# MSPM0G110X register map
Vendor: Texas Instruments; File version: This preliminary header file does not have a version number - build date: 2023-02-21 16:25:48
CPU: CM0 r0p1, little endian, MPU, no FPU, 3 interrupt priority bits
Registers are 32-bit, read-write, reset 0x0 unless marked. A register's access mark holds for its fields unless they carry their own. Offsets are from the block's base; [hi:lo] are bit positions.

## WWDT1 — WWDT
Base 0x40082000
Same registers: WWDT0 0x40080000
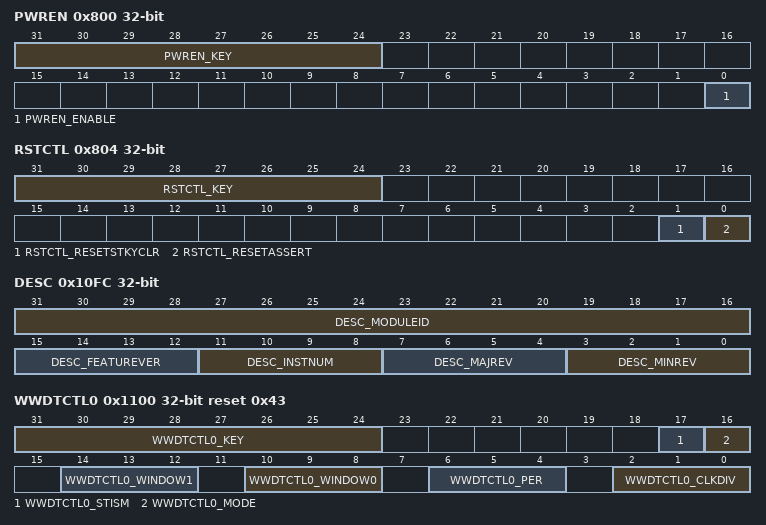
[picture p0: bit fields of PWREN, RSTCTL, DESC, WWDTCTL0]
0x800 PWREN — Power enable
  [31:24] PWREN_KEY wo — KEY to allow Power State Change
    38=PWREN_KEY_UNLOCK_W (_TO_UNLOCK_W_)
  [0] PWREN_ENABLE — Enable the power Note: For safety devices the power cannot be disabled once enabled.
    0=PWREN_ENABLE_DISABLE (DISABLE); 1=PWREN_ENABLE_ENABLE (ENABLE)
0x804 RSTCTL wo — Reset Control
  [31:24] RSTCTL_KEY — Unlock key
    177=RSTCTL_KEY_UNLOCK_W (_TO_UNLOCK_W_)
  [1] RSTCTL_RESETSTKYCLR — Clear [GPRCM.STAT.RESETSTKY]
    0=RSTCTL_RESETSTKYCLR_NOP (NOP); 1=RSTCTL_RESETSTKYCLR_CLR (CLR)
  [0] RSTCTL_RESETASSERT — Assert reset to the peripheral Note: For safety devices a watchdog reset by software is not possible.
    0=RSTCTL_RESETASSERT_NOP (NOP); 1=RSTCTL_RESETASSERT_ASSERT (ASSERT)
0x814 STAT ro — Status Register
  [16] STAT_RESETSTKY — This bit indicates, if the peripheral was reset, since this bit was cleared by RESETSTKYCLR in the RSTCTL register
    0=STAT_RESETSTKY_NORES (NORES); 1=STAT_RESETSTKY_RESET (RESET)
0x1018 PDBGCTL — Peripheral Debug Control
  [0] PDBGCTL_FREE — Free run control
    0=PDBGCTL_FREE_STOP (STOP); 1=PDBGCTL_FREE_RUN (RUN)
0x1020 IIDX ro — Interrupt index
  [4:0] IIDX_STAT — Module Interrupt Vector Value. This register provides the highest priority interrupt index. A read clears the corresponding interrupt flag in RIS and MISC.
    0=IIDX_STAT_NO_INTR (NO_INTR); 1=IIDX_STAT_INTTIM (INTTIM)
0x1028 IMASK — Interrupt mask
  [0] IMASK_INTTIM — Interval Timer Interrupt.
    0=IMASK_INTTIM_CLR (CLR); 1=IMASK_INTTIM_SET (SET)
0x1030 RIS ro — Raw interrupt status
  [0] RIS_INTTIM — Interval Timer Interrupt.
    0=RIS_INTTIM_CLR (CLR); 1=RIS_INTTIM_SET (SET)
0x1038 MIS ro — Masked interrupt status
  [0] MIS_INTTIM — Interval Timer Interrupt.
    0=MIS_INTTIM_CLR (CLR); 1=MIS_INTTIM_SET (SET)
0x1040 ISET wo — Interrupt set
  [0] ISET_INTTIM — Interval Timer Interrupt.
    0=ISET_INTTIM_NO_EFFECT (NO_EFFECT); 1=ISET_INTTIM_SET (SET)
0x1048 ICLR wo — Interrupt clear
  [0] ICLR_INTTIM — Interval Timer Interrupt.
    0=ICLR_INTTIM_NO_EFFECT (NO_EFFECT); 1=ICLR_INTTIM_CLR (CLR)
0x10E0 EVT_MODE — Event Mode
  [1:0] EVT_MODE_INT0_CFG ro — Event line mode select for event corresponding to [IPSTANDARD.INT_EVENT][0]
    0=EVT_MODE_INT0_CFG_DISABLE (DISABLE); 1=EVT_MODE_INT0_CFG_SOFTWARE (SOFTWARE); 2=EVT_MODE_INT0_CFG_HARDWARE (HARDWARE)
0x10FC DESC ro — Module Description
  [31:16] DESC_MODULEID — Module identification contains a unique peripheral identification number. The assignments are maintained in a central database for all of the platform modules to ensure uniqueness.
  [15:12] DESC_FEATUREVER — Feature Set for the module *instance*
  [11:8] DESC_INSTNUM — Instance Number within the device. This will be a parameter to the RTL for modules that can have multiple instances
  [7:4] DESC_MAJREV — Major rev of the IP
  [3:0] DESC_MINREV — Minor rev of the IP
0x1100 WWDTCTL0 rw-once reset 0x43 — Window Watchdog Timer Control Register 0
  [31:24] WWDTCTL0_KEY write-once — KEY to allow write access to this register. Writing to this register with an incorrect key activates the WWDT error signal to the ESM. Read as 0.
    201=WWDTCTL0_KEY_UNLOCK_W (_TO_UNLOCK_W_)
  [17] WWDTCTL0_STISM — Stop In Sleep Mode. The functionality of this bit requires that POLICY.HWCEN = 0. If POLICY.HWCEN = 1 the WWDT resets during sleep and needs re-configuration. Note: This bit has no effect for the global Window Watchdog as Sleep Mode is not supported.
    0=WWDTCTL0_STISM_CONT (CONT); 1=WWDTCTL0_STISM_STOP (STOP)
  [16] WWDTCTL0_MODE — Window Watchdog Timer Mode
    0=WWDTCTL0_MODE_WINDOW (WINDOW); 1=WWDTCTL0_MODE_INTERVAL (INTERVAL)
  [14:12] WWDTCTL0_WINDOW1 — Closed window period in percentage of the timer interval. WWDTCTL1.WINSEL determines the active window setting (WWDTCTL0.WINDOW0 or WWDTCTL0.WINDOW1).
    0=WWDTCTL0_WINDOW1_SIZE_0 (SIZE_0); 1=WWDTCTL0_WINDOW1_SIZE_12 (SIZE_12); 2=WWDTCTL0_WINDOW1_SIZE_18 (SIZE_18); 3=WWDTCTL0_WINDOW1_SIZE_25 (SIZE_25); 4=WWDTCTL0_WINDOW1_SIZE_50 (SIZE_50); 5=WWDTCTL0_WINDOW1_SIZE_75 (SIZE_75); 6=WWDTCTL0_WINDOW1_SIZE_81 (SIZE_81); 7=WWDTCTL0_WINDOW1_SIZE_87 (SIZE_87)
  [10:8] WWDTCTL0_WINDOW0 — Closed window period in percentage of the timer interval. WWDTCTL1.WINSEL determines the active window setting (WWDTCTL0.WINDOW0 or WWDTCTL0.WINDOW1).
    0=WWDTCTL0_WINDOW0_SIZE_0 (SIZE_0); 1=WWDTCTL0_WINDOW0_SIZE_12 (SIZE_12); 2=WWDTCTL0_WINDOW0_SIZE_18 (SIZE_18); 3=WWDTCTL0_WINDOW0_SIZE_25 (SIZE_25); 4=WWDTCTL0_WINDOW0_SIZE_50 (SIZE_50); 5=WWDTCTL0_WINDOW0_SIZE_75 (SIZE_75); 6=WWDTCTL0_WINDOW0_SIZE_81 (SIZE_81); 7=WWDTCTL0_WINDOW0_SIZE_87 (SIZE_87)
  [6:4] WWDTCTL0_PER — Timer Period of the WWDT. These bits select the total watchdog timer count.
    0=WWDTCTL0_PER_EN_25 (EN_25); 1=WWDTCTL0_PER_EN_21 (EN_21); 2=WWDTCTL0_PER_EN_18 (EN_18); 3=WWDTCTL0_PER_EN_15 (EN_15); 4=WWDTCTL0_PER_EN_12 (EN_12); 5=WWDTCTL0_PER_EN_10 (EN_10); 6=WWDTCTL0_PER_EN_8 (EN_8); 7=WWDTCTL0_PER_EN_6 (EN_6)
  [2:0] WWDTCTL0_CLKDIV — Module Clock Divider, Divide the clock source by CLKDIV+1. Divider values from /1 to /8 are possible. The clock divider is currently 4 bits. Bit 4 has no effect and should always be written with 0.
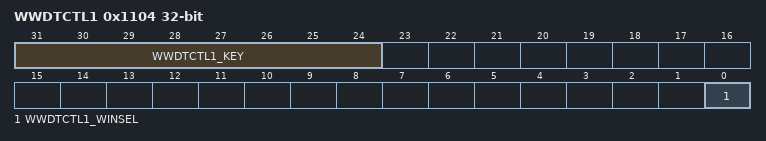
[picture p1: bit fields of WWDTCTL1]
0x1104 WWDTCTL1 — Window Watchdog Timer Control Register 0
  [31:24] WWDTCTL1_KEY wo — KEY to allow write access to this register. Writing to this register with an incorrect key activates the WWDT error signal to the ESM. Read as 0.
    190=WWDTCTL1_KEY_UNLOCK_W (_TO_UNLOCK_W_)
  [0] WWDTCTL1_WINSEL — Close Window Select
    0=WWDTCTL1_WINSEL_WIN0 (WIN0); 1=WWDTCTL1_WINSEL_WIN1 (WIN1)
0x1108 WWDTCNTRST — Window Watchdog Timer Counter Reset Register
  [31:0] WWDTCNTRST_RESTART — Window Watchdog Timer Counter Restart Writing 00A7h to this register restarts the WWDT Counter. Writing any other value causes an error generation to the ESM. Read as 0.
0x110C WWDTSTAT ro — Window Watchdog Timer Status Register
  [0] WWDTSTAT_RUN — Watchdog running status flag.
    0=WWDTSTAT_RUN_OFF (OFF); 1=WWDTSTAT_RUN_ON (ON)
